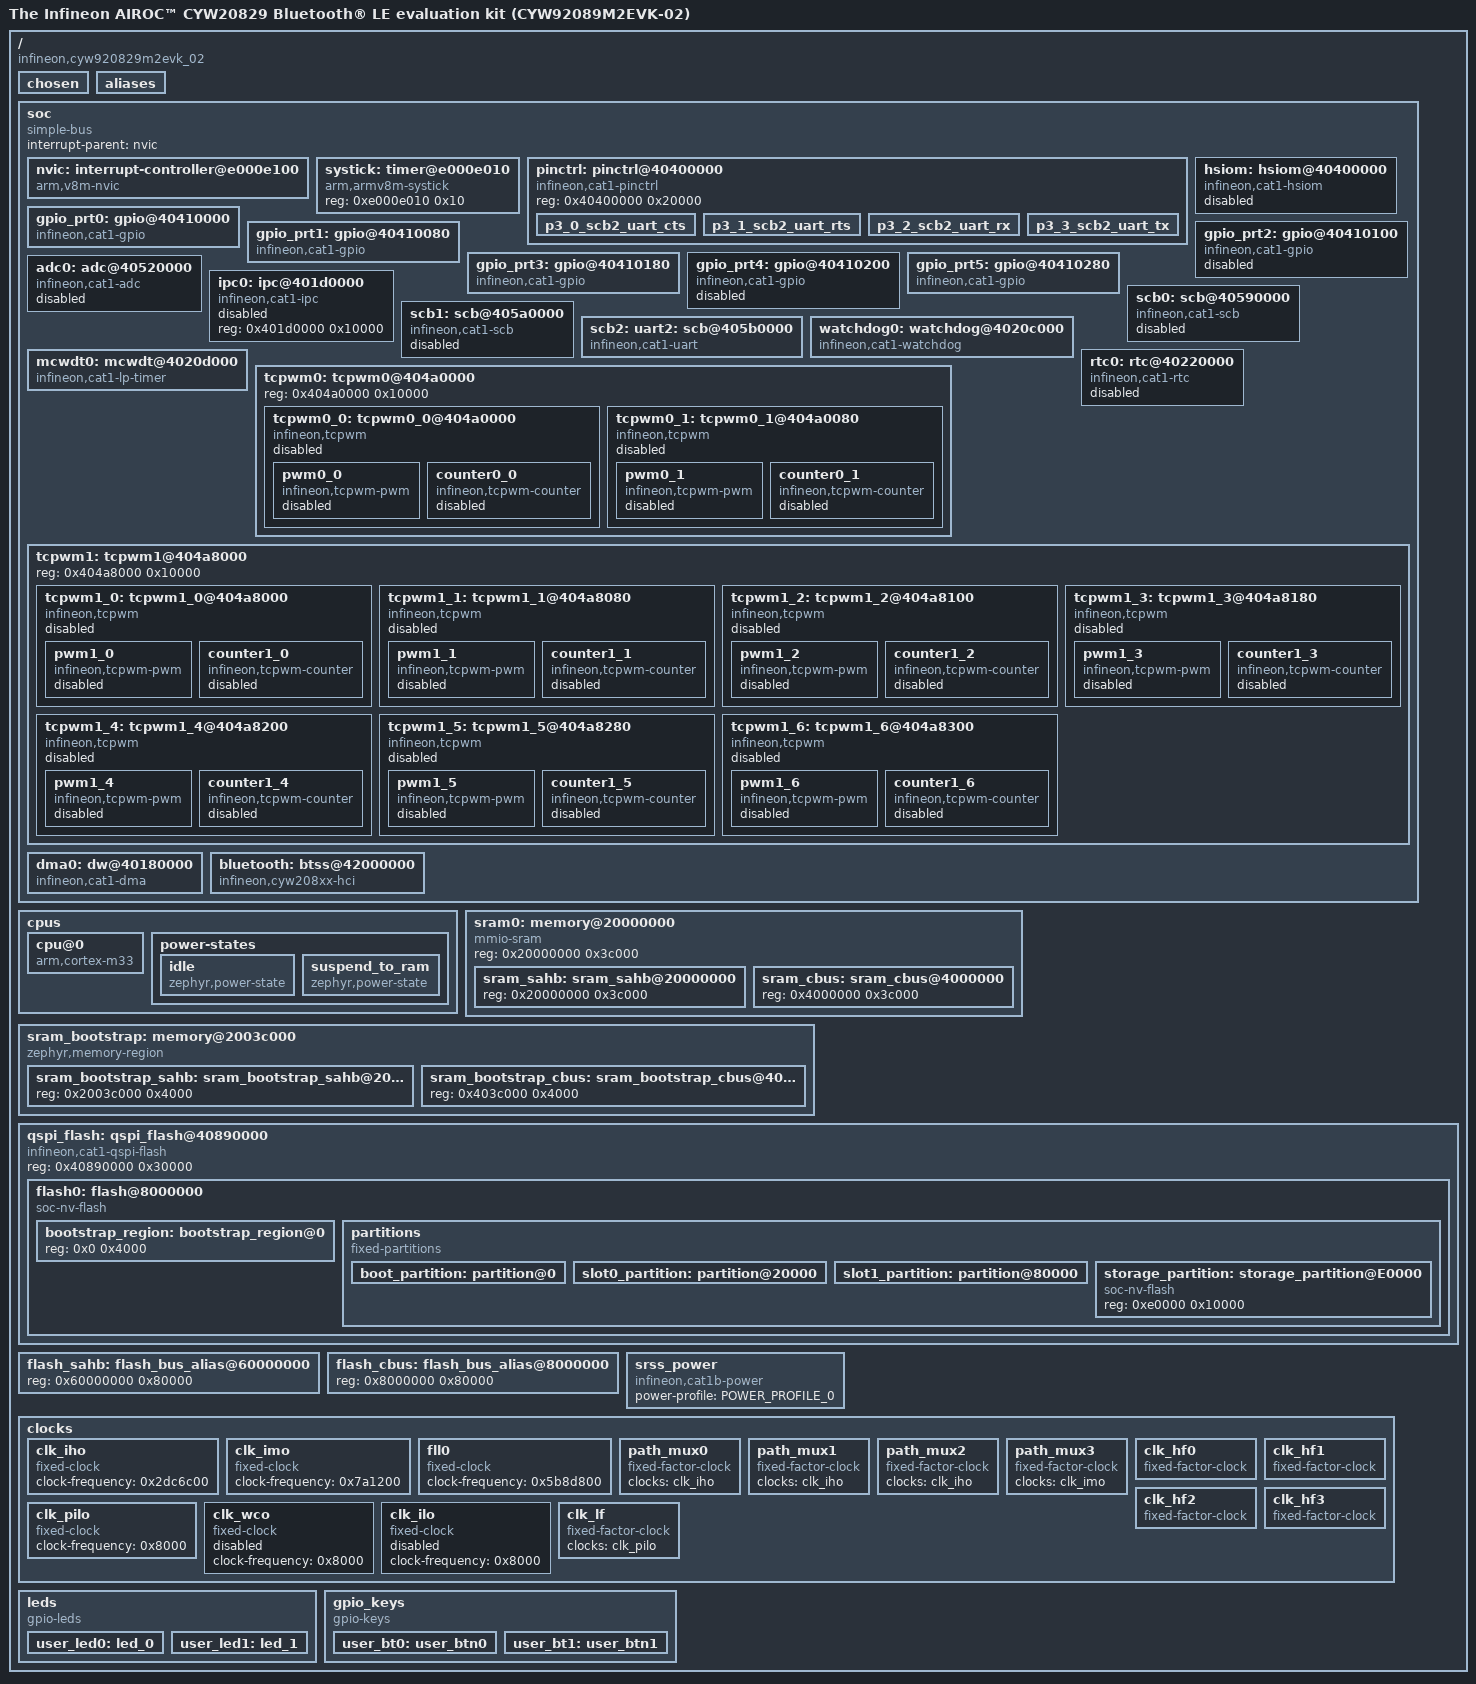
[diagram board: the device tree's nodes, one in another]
/dts-v1/;

/* node '/' defined in zephyr/dts/common/skeleton.dtsi:9 */
/ {
	#address-cells = < 0x1 >;                                                               /* in zephyr/dts/common/skeleton.dtsi:10 */
	#size-cells = < 0x1 >;                                                                  /* in zephyr/dts/common/skeleton.dtsi:11 */
	model = "The Infineon AIROC™ CYW20829 Bluetooth® LE evaluation kit (CYW92089M2EVK-02)"; /* in zephyr/boards/infineon/cyw920829m2evk_02/cyw920829m2evk_02.dts:13 */
	compatible = "infineon,cyw920829m2evk_02",
	             "infineon,CYW20829";                                                       /* in zephyr/boards/infineon/cyw920829m2evk_02/cyw920829m2evk_02.dts:14 */

	/* node '/chosen' defined in zephyr/dts/common/skeleton.dtsi:13 */
	chosen {
		zephyr,sram = &sram0;                     /* in zephyr/boards/infineon/cyw920829m2evk_02/cyw920829m2evk_02.dts:21 */
		zephyr,flash = &flash0;                   /* in zephyr/boards/infineon/cyw920829m2evk_02/cyw920829m2evk_02.dts:22 */
		zephyr,code-partition = &slot0_partition; /* in zephyr/boards/infineon/cyw920829m2evk_02/cyw920829m2evk_02.dts:23 */
		zephyr,console = &uart2;                  /* in zephyr/boards/infineon/cyw920829m2evk_02/cyw920829m2evk_02.dts:24 */
		zephyr,shell-uart = &uart2;               /* in zephyr/boards/infineon/cyw920829m2evk_02/cyw920829m2evk_02.dts:25 */
		zephyr,bt-hci = &bluetooth;               /* in zephyr/boards/infineon/cyw920829m2evk_02/cyw920829m2evk_02.dts:26 */
	};

	/* node '/aliases' defined in zephyr/dts/common/skeleton.dtsi:15 */
	aliases {
		led0 = &user_led0;      /* in zephyr/boards/infineon/cyw920829m2evk_02/cyw920829m2evk_02-common.dtsi:10 */
		led1 = &user_led1;      /* in zephyr/boards/infineon/cyw920829m2evk_02/cyw920829m2evk_02-common.dtsi:11 */
		sw0 = &user_bt0;        /* in zephyr/boards/infineon/cyw920829m2evk_02/cyw920829m2evk_02-common.dtsi:12 */
		sw1 = &user_bt1;        /* in zephyr/boards/infineon/cyw920829m2evk_02/cyw920829m2evk_02-common.dtsi:13 */
		watchdog0 = &watchdog0; /* in zephyr/boards/infineon/cyw920829m2evk_02/cyw920829m2evk_02.dts:17 */
	};

	/* node '/soc' defined in zephyr/dts/arm/armv8-m.dtsi:6 */
	soc {
		#address-cells = < 0x1 >;     /* in zephyr/dts/arm/armv8-m.dtsi:7 */
		#size-cells = < 0x1 >;        /* in zephyr/dts/arm/armv8-m.dtsi:8 */
		compatible = "simple-bus";    /* in zephyr/dts/arm/armv8-m.dtsi:9 */
		interrupt-parent = < &nvic >; /* in zephyr/dts/arm/armv8-m.dtsi:10 */
		ranges;                       /* in zephyr/dts/arm/armv8-m.dtsi:11 */

		/* node '/soc/interrupt-controller@e000e100' defined in zephyr/dts/arm/armv8-m.dtsi:13 */
		nvic: interrupt-controller@e000e100 {
			#address-cells = < 0x1 >;            /* in zephyr/dts/arm/armv8-m.dtsi:14 */
			compatible = "arm,v8m-nvic";         /* in zephyr/dts/arm/armv8-m.dtsi:15 */
			reg = < 0xe000e100 0xc00 >;          /* in zephyr/dts/arm/armv8-m.dtsi:16 */
			interrupt-controller;                /* in zephyr/dts/arm/armv8-m.dtsi:17 */
			#interrupt-cells = < 0x2 >;          /* in zephyr/dts/arm/armv8-m.dtsi:18 */
			arm,num-irq-priority-bits = < 0x3 >; /* in zephyr/boards/infineon/cyw920829m2evk_02/cyw920829m2evk_02.dts:31 */
			phandle = < 0x1 >;                   /* in zephyr/dts/arm/armv8-m.dtsi:10 */
		};

		/* node '/soc/timer@e000e010' defined in zephyr/dts/arm/armv8-m.dtsi:21 */
		systick: timer@e000e010 {
			compatible = "arm,armv8m-systick"; /* in zephyr/dts/arm/armv8-m.dtsi:22 */
			reg = < 0xe000e010 0x10 >;         /* in zephyr/dts/arm/armv8-m.dtsi:23 */
		};

		/* node '/soc/pinctrl@40400000' defined in zephyr/dts/arm/infineon/cat1b/cyw20829/cyw20829.dtsi:93 */
		pinctrl: pinctrl@40400000 {
			compatible = "infineon,cat1-pinctrl"; /* in zephyr/dts/arm/infineon/cat1b/cyw20829/cyw20829.dtsi:94 */
			reg = < 0x40400000 0x20000 >;         /* in zephyr/dts/arm/infineon/cat1b/cyw20829/cyw20829.dtsi:95 */

			/* node '/soc/pinctrl@40400000/p3_0_scb2_uart_cts' defined in zephyr/dts/arm/infineon/cat1b/cyw20829/cyw20829.56-qfn.dtsi:260 */
			p3_0_scb2_uart_cts: p3_0_scb2_uart_cts {
				pinmux = < 0x120003 >; /* in zephyr/dts/arm/infineon/cat1b/cyw20829/cyw20829.56-qfn.dtsi:261 */
				input-enable;          /* in zephyr/boards/infineon/cyw920829m2evk_02/cyw920829m2evk_02-pinctrl.dtsi:20 */
				phandle = < 0x5 >;     /* in zephyr/boards/infineon/cyw920829m2evk_02/cyw920829m2evk_02.dts:40 */
			};

			/* node '/soc/pinctrl@40400000/p3_1_scb2_uart_rts' defined in zephyr/dts/arm/infineon/cat1b/cyw20829/cyw20829.56-qfn.dtsi:277 */
			p3_1_scb2_uart_rts: p3_1_scb2_uart_rts {
				pinmux = < 0x120103 >; /* in zephyr/dts/arm/infineon/cat1b/cyw20829/cyw20829.56-qfn.dtsi:278 */
				drive-push-pull;       /* in zephyr/boards/infineon/cyw920829m2evk_02/cyw920829m2evk_02-pinctrl.dtsi:16 */
				phandle = < 0x4 >;     /* in zephyr/boards/infineon/cyw920829m2evk_02/cyw920829m2evk_02.dts:40 */
			};

			/* node '/soc/pinctrl@40400000/p3_2_scb2_uart_rx' defined in zephyr/dts/arm/infineon/cat1b/cyw20829/cyw20829.56-qfn.dtsi:286 */
			p3_2_scb2_uart_rx: p3_2_scb2_uart_rx {
				pinmux = < 0x120203 >; /* in zephyr/dts/arm/infineon/cat1b/cyw20829/cyw20829.56-qfn.dtsi:287 */
				input-enable;          /* in zephyr/boards/infineon/cyw920829m2evk_02/cyw920829m2evk_02-pinctrl.dtsi:12 */
				phandle = < 0x3 >;     /* in zephyr/boards/infineon/cyw920829m2evk_02/cyw920829m2evk_02.dts:40 */
			};

			/* node '/soc/pinctrl@40400000/p3_3_scb2_uart_tx' defined in zephyr/dts/arm/infineon/cat1b/cyw20829/cyw20829.56-qfn.dtsi:295 */
			p3_3_scb2_uart_tx: p3_3_scb2_uart_tx {
				pinmux = < 0x120303 >; /* in zephyr/dts/arm/infineon/cat1b/cyw20829/cyw20829.56-qfn.dtsi:296 */
				drive-push-pull;       /* in zephyr/boards/infineon/cyw920829m2evk_02/cyw920829m2evk_02-pinctrl.dtsi:8 */
				phandle = < 0x2 >;     /* in zephyr/boards/infineon/cyw920829m2evk_02/cyw920829m2evk_02.dts:40 */
			};
		};

		/* node '/soc/hsiom@40400000' defined in zephyr/dts/arm/infineon/cat1b/cyw20829/cyw20829.dtsi:98 */
		hsiom: hsiom@40400000 {
			compatible = "infineon,cat1-hsiom"; /* in zephyr/dts/arm/infineon/cat1b/cyw20829/cyw20829.dtsi:99 */
			reg = < 0x40400000 0x4000 >;        /* in zephyr/dts/arm/infineon/cat1b/cyw20829/cyw20829.dtsi:100 */
			interrupts = < 0x7 0x4 >,
			             < 0x6 0x4 >;           /* in zephyr/dts/arm/infineon/cat1b/cyw20829/cyw20829.dtsi:101 */
			status = "disabled";                /* in zephyr/dts/arm/infineon/cat1b/cyw20829/cyw20829.dtsi:102 */
		};

		/* node '/soc/gpio@40410000' defined in zephyr/dts/arm/infineon/cat1b/cyw20829/cyw20829.dtsi:105 */
		gpio_prt0: gpio@40410000 {
			compatible = "infineon,cat1-gpio"; /* in zephyr/dts/arm/infineon/cat1b/cyw20829/cyw20829.dtsi:106 */
			reg = < 0x40410000 0x80 >;         /* in zephyr/dts/arm/infineon/cat1b/cyw20829/cyw20829.dtsi:107 */
			interrupts = < 0x0 0x4 >;          /* in zephyr/dts/arm/infineon/cat1b/cyw20829/cyw20829.dtsi:108 */
			gpio-controller;                   /* in zephyr/dts/arm/infineon/cat1b/cyw20829/cyw20829.dtsi:109 */
			ngpios = < 0x6 >;                  /* in zephyr/dts/arm/infineon/cat1b/cyw20829/cyw20829.dtsi:110 */
			#gpio-cells = < 0x2 >;             /* in zephyr/dts/arm/infineon/cat1b/cyw20829/cyw20829.dtsi:112 */
			status = "okay";                   /* in zephyr/boards/infineon/cyw920829m2evk_02/cyw920829m2evk_02-common.dtsi:48 */
			phandle = < 0x11 >;                /* in zephyr/boards/infineon/cyw920829m2evk_02/cyw920829m2evk_02-common.dtsi:35 */
		};

		/* node '/soc/gpio@40410080' defined in zephyr/dts/arm/infineon/cat1b/cyw20829/cyw20829.dtsi:115 */
		gpio_prt1: gpio@40410080 {
			compatible = "infineon,cat1-gpio"; /* in zephyr/dts/arm/infineon/cat1b/cyw20829/cyw20829.dtsi:116 */
			reg = < 0x40410080 0x80 >;         /* in zephyr/dts/arm/infineon/cat1b/cyw20829/cyw20829.dtsi:117 */
			interrupts = < 0x1 0x4 >;          /* in zephyr/dts/arm/infineon/cat1b/cyw20829/cyw20829.dtsi:118 */
			gpio-controller;                   /* in zephyr/dts/arm/infineon/cat1b/cyw20829/cyw20829.dtsi:119 */
			ngpios = < 0x7 >;                  /* in zephyr/dts/arm/infineon/cat1b/cyw20829/cyw20829.dtsi:120 */
			#gpio-cells = < 0x2 >;             /* in zephyr/dts/arm/infineon/cat1b/cyw20829/cyw20829.dtsi:122 */
			status = "okay";                   /* in zephyr/boards/infineon/cyw920829m2evk_02/cyw920829m2evk_02-common.dtsi:52 */
			phandle = < 0xf >;                 /* in zephyr/boards/infineon/cyw920829m2evk_02/cyw920829m2evk_02-common.dtsi:21 */
		};

		/* node '/soc/gpio@40410100' defined in zephyr/dts/arm/infineon/cat1b/cyw20829/cyw20829.dtsi:125 */
		gpio_prt2: gpio@40410100 {
			compatible = "infineon,cat1-gpio"; /* in zephyr/dts/arm/infineon/cat1b/cyw20829/cyw20829.dtsi:126 */
			reg = < 0x40410100 0x80 >;         /* in zephyr/dts/arm/infineon/cat1b/cyw20829/cyw20829.dtsi:127 */
			interrupts = < 0x2 0x4 >;          /* in zephyr/dts/arm/infineon/cat1b/cyw20829/cyw20829.dtsi:128 */
			gpio-controller;                   /* in zephyr/dts/arm/infineon/cat1b/cyw20829/cyw20829.dtsi:129 */
			ngpios = < 0x6 >;                  /* in zephyr/dts/arm/infineon/cat1b/cyw20829/cyw20829.dtsi:130 */
			status = "disabled";               /* in zephyr/dts/arm/infineon/cat1b/cyw20829/cyw20829.dtsi:131 */
			#gpio-cells = < 0x2 >;             /* in zephyr/dts/arm/infineon/cat1b/cyw20829/cyw20829.dtsi:132 */
		};

		/* node '/soc/gpio@40410180' defined in zephyr/dts/arm/infineon/cat1b/cyw20829/cyw20829.dtsi:135 */
		gpio_prt3: gpio@40410180 {
			compatible = "infineon,cat1-gpio"; /* in zephyr/dts/arm/infineon/cat1b/cyw20829/cyw20829.dtsi:136 */
			reg = < 0x40410180 0x80 >;         /* in zephyr/dts/arm/infineon/cat1b/cyw20829/cyw20829.dtsi:137 */
			interrupts = < 0x3 0x4 >;          /* in zephyr/dts/arm/infineon/cat1b/cyw20829/cyw20829.dtsi:138 */
			gpio-controller;                   /* in zephyr/dts/arm/infineon/cat1b/cyw20829/cyw20829.dtsi:139 */
			ngpios = < 0x8 >;                  /* in zephyr/dts/arm/infineon/cat1b/cyw20829/cyw20829.dtsi:140 */
			#gpio-cells = < 0x2 >;             /* in zephyr/dts/arm/infineon/cat1b/cyw20829/cyw20829.dtsi:142 */
			status = "okay";                   /* in zephyr/boards/infineon/cyw920829m2evk_02/cyw920829m2evk_02-common.dtsi:56 */
		};

		/* node '/soc/gpio@40410200' defined in zephyr/dts/arm/infineon/cat1b/cyw20829/cyw20829.dtsi:145 */
		gpio_prt4: gpio@40410200 {
			compatible = "infineon,cat1-gpio"; /* in zephyr/dts/arm/infineon/cat1b/cyw20829/cyw20829.dtsi:146 */
			reg = < 0x40410200 0x80 >;         /* in zephyr/dts/arm/infineon/cat1b/cyw20829/cyw20829.dtsi:147 */
			interrupts = < 0x4 0x4 >;          /* in zephyr/dts/arm/infineon/cat1b/cyw20829/cyw20829.dtsi:148 */
			gpio-controller;                   /* in zephyr/dts/arm/infineon/cat1b/cyw20829/cyw20829.dtsi:149 */
			ngpios = < 0x2 >;                  /* in zephyr/dts/arm/infineon/cat1b/cyw20829/cyw20829.dtsi:150 */
			status = "disabled";               /* in zephyr/dts/arm/infineon/cat1b/cyw20829/cyw20829.dtsi:151 */
			#gpio-cells = < 0x2 >;             /* in zephyr/dts/arm/infineon/cat1b/cyw20829/cyw20829.dtsi:152 */
		};

		/* node '/soc/gpio@40410280' defined in zephyr/dts/arm/infineon/cat1b/cyw20829/cyw20829.dtsi:155 */
		gpio_prt5: gpio@40410280 {
			compatible = "infineon,cat1-gpio"; /* in zephyr/dts/arm/infineon/cat1b/cyw20829/cyw20829.dtsi:156 */
			reg = < 0x40410280 0x80 >;         /* in zephyr/dts/arm/infineon/cat1b/cyw20829/cyw20829.dtsi:157 */
			interrupts = < 0x5 0x4 >;          /* in zephyr/dts/arm/infineon/cat1b/cyw20829/cyw20829.dtsi:158 */
			gpio-controller;                   /* in zephyr/dts/arm/infineon/cat1b/cyw20829/cyw20829.dtsi:159 */
			ngpios = < 0x3 >;                  /* in zephyr/dts/arm/infineon/cat1b/cyw20829/cyw20829.dtsi:160 */
			#gpio-cells = < 0x2 >;             /* in zephyr/dts/arm/infineon/cat1b/cyw20829/cyw20829.dtsi:162 */
			status = "okay";                   /* in zephyr/boards/infineon/cyw920829m2evk_02/cyw920829m2evk_02-common.dtsi:60 */
			phandle = < 0x10 >;                /* in zephyr/boards/infineon/cyw920829m2evk_02/cyw920829m2evk_02-common.dtsi:26 */
		};

		/* node '/soc/adc@40520000' defined in zephyr/dts/arm/infineon/cat1b/cyw20829/cyw20829.dtsi:165 */
		adc0: adc@40520000 {
			compatible = "infineon,cat1-adc"; /* in zephyr/dts/arm/infineon/cat1b/cyw20829/cyw20829.dtsi:166 */
			reg = < 0x40520000 0x10000 >;     /* in zephyr/dts/arm/infineon/cat1b/cyw20829/cyw20829.dtsi:167 */
			interrupts = < 0x43 0x6 >;        /* in zephyr/dts/arm/infineon/cat1b/cyw20829/cyw20829.dtsi:168 */
			status = "disabled";              /* in zephyr/dts/arm/infineon/cat1b/cyw20829/cyw20829.dtsi:169 */
			#io-channel-cells = < 0x1 >;      /* in zephyr/dts/arm/infineon/cat1b/cyw20829/cyw20829.dtsi:170 */
		};

		/* node '/soc/ipc@401d0000' defined in zephyr/dts/arm/infineon/cat1b/cyw20829/cyw20829.dtsi:173 */
		ipc0: ipc@401d0000 {
			compatible = "infineon,cat1-ipc"; /* in zephyr/dts/arm/infineon/cat1b/cyw20829/cyw20829.dtsi:174 */
			reg = < 0x401d0000 0x10000 >;     /* in zephyr/dts/arm/infineon/cat1b/cyw20829/cyw20829.dtsi:175 */
			status = "disabled";              /* in zephyr/dts/arm/infineon/cat1b/cyw20829/cyw20829.dtsi:176 */
			#ipc-config-cells = < 0x3 >;      /* in zephyr/dts/arm/infineon/cat1b/cyw20829/cyw20829.dtsi:177 */
		};

		/* node '/soc/scb@40590000' defined in zephyr/dts/arm/infineon/cat1b/cyw20829/cyw20829.dtsi:180 */
		scb0: scb@40590000 {
			compatible = "infineon,cat1-scb"; /* in zephyr/dts/arm/infineon/cat1b/cyw20829/cyw20829.dtsi:181 */
			reg = < 0x40590000 0xfd0 >;       /* in zephyr/dts/arm/infineon/cat1b/cyw20829/cyw20829.dtsi:182 */
			interrupts = < 0x8 0x4 >;         /* in zephyr/dts/arm/infineon/cat1b/cyw20829/cyw20829.dtsi:183 */
			status = "disabled";              /* in zephyr/dts/arm/infineon/cat1b/cyw20829/cyw20829.dtsi:184 */
		};

		/* node '/soc/scb@405a0000' defined in zephyr/dts/arm/infineon/cat1b/cyw20829/cyw20829.dtsi:187 */
		scb1: scb@405a0000 {
			compatible = "infineon,cat1-scb"; /* in zephyr/dts/arm/infineon/cat1b/cyw20829/cyw20829.dtsi:188 */
			reg = < 0x405a0000 0xfd0 >;       /* in zephyr/dts/arm/infineon/cat1b/cyw20829/cyw20829.dtsi:189 */
			interrupts = < 0x11 0x4 >;        /* in zephyr/dts/arm/infineon/cat1b/cyw20829/cyw20829.dtsi:190 */
			status = "disabled";              /* in zephyr/dts/arm/infineon/cat1b/cyw20829/cyw20829.dtsi:191 */
		};

		/* node '/soc/scb@405b0000' defined in zephyr/dts/arm/infineon/cat1b/cyw20829/cyw20829.dtsi:194 */
		scb2: uart2: scb@405b0000 {
			reg = < 0x405b0000 0xfd0 >;                                                                    /* in zephyr/dts/arm/infineon/cat1b/cyw20829/cyw20829.dtsi:196 */
			interrupts = < 0x12 0x4 >;                                                                     /* in zephyr/dts/arm/infineon/cat1b/cyw20829/cyw20829.dtsi:197 */
			compatible = "infineon,cat1-uart";                                                             /* in zephyr/boards/infineon/cyw920829m2evk_02/cyw920829m2evk_02.dts:35 */
			status = "okay";                                                                               /* in zephyr/boards/infineon/cyw920829m2evk_02/cyw920829m2evk_02.dts:36 */
			current-speed = < 0x1c200 >;                                                                   /* in zephyr/boards/infineon/cyw920829m2evk_02/cyw920829m2evk_02.dts:37 */
			hw-flow-control;                                                                               /* in zephyr/boards/infineon/cyw920829m2evk_02/cyw920829m2evk_02.dts:38 */
			pinctrl-0 = < &p3_3_scb2_uart_tx &p3_2_scb2_uart_rx &p3_1_scb2_uart_rts &p3_0_scb2_uart_cts >; /* in zephyr/boards/infineon/cyw920829m2evk_02/cyw920829m2evk_02.dts:40 */
			pinctrl-names = "default";                                                                     /* in zephyr/boards/infineon/cyw920829m2evk_02/cyw920829m2evk_02.dts:41 */
			dmas = < &dma0 0x8 >,
			       < &dma0 0x9 >;                                                                          /* in zephyr/boards/infineon/cyw920829m2evk_02/cyw920829m2evk_02.dts:43 */
			dma-names = "tx",
			            "rx";                                                                              /* in zephyr/boards/infineon/cyw920829m2evk_02/cyw920829m2evk_02.dts:44 */
		};

		/* node '/soc/watchdog@4020c000' defined in zephyr/dts/arm/infineon/cat1b/cyw20829/cyw20829.dtsi:201 */
		watchdog0: watchdog@4020c000 {
			compatible = "infineon,cat1-watchdog"; /* in zephyr/dts/arm/infineon/cat1b/cyw20829/cyw20829.dtsi:202 */
			reg = < 0x4020c000 0x10 >;             /* in zephyr/dts/arm/infineon/cat1b/cyw20829/cyw20829.dtsi:203 */
			interrupts = < 0xf 0x4 >;              /* in zephyr/dts/arm/infineon/cat1b/cyw20829/cyw20829.dtsi:204 */
			status = "okay";                       /* in zephyr/boards/infineon/cyw920829m2evk_02/cyw920829m2evk_02.dts:92 */
		};

		/* node '/soc/mcwdt@4020d000' defined in zephyr/dts/arm/infineon/cat1b/cyw20829/cyw20829.dtsi:208 */
		mcwdt0: mcwdt@4020d000 {
			compatible = "infineon,cat1-lp-timer"; /* in zephyr/dts/arm/infineon/cat1b/cyw20829/cyw20829.dtsi:209 */
			reg = < 0x4020d000 0x40 >;             /* in zephyr/dts/arm/infineon/cat1b/cyw20829/cyw20829.dtsi:210 */
			interrupts = < 0x9 0x4 >;              /* in zephyr/dts/arm/infineon/cat1b/cyw20829/cyw20829.dtsi:211 */
			status = "okay";                       /* in zephyr/boards/infineon/cyw920829m2evk_02/cyw920829m2evk_02.dts:96 */
		};

		/* node '/soc/rtc@40220000' defined in zephyr/dts/arm/infineon/cat1b/cyw20829/cyw20829.dtsi:215 */
		rtc0: rtc@40220000 {
			compatible = "infineon,cat1-rtc"; /* in zephyr/dts/arm/infineon/cat1b/cyw20829/cyw20829.dtsi:216 */
			reg = < 0x40220000 0x10000 >;     /* in zephyr/dts/arm/infineon/cat1b/cyw20829/cyw20829.dtsi:217 */
			interrupts = < 0xa 0x6 >;         /* in zephyr/dts/arm/infineon/cat1b/cyw20829/cyw20829.dtsi:218 */
			alarms-count = < 0x2 >;           /* in zephyr/dts/arm/infineon/cat1b/cyw20829/cyw20829.dtsi:219 */
			status = "disabled";              /* in zephyr/dts/arm/infineon/cat1b/cyw20829/cyw20829.dtsi:220 */
		};

		/* node '/soc/tcpwm0@404a0000' defined in zephyr/dts/arm/infineon/cat1b/cyw20829/cyw20829.dtsi:223 */
		tcpwm0: tcpwm0@404a0000 {
			reg = < 0x404a0000 0x10000 >; /* in zephyr/dts/arm/infineon/cat1b/cyw20829/cyw20829.dtsi:224 */
			#address-cells = < 0x1 >;     /* in zephyr/dts/arm/infineon/cat1b/cyw20829/cyw20829.dtsi:225 */
			#size-cells = < 0x1 >;        /* in zephyr/dts/arm/infineon/cat1b/cyw20829/cyw20829.dtsi:226 */

			/* node '/soc/tcpwm0@404a0000/tcpwm0_0@404a0000' defined in zephyr/dts/arm/infineon/cat1b/cyw20829/cyw20829.dtsi:228 */
			tcpwm0_0: tcpwm0_0@404a0000 {
				compatible = "infineon,tcpwm"; /* in zephyr/dts/arm/infineon/cat1b/cyw20829/cyw20829.dtsi:229 */
				reg = < 0x404a0000 0x80 >;     /* in zephyr/dts/arm/infineon/cat1b/cyw20829/cyw20829.dtsi:230 */
				interrupts = < 0x2a 0x4 >;     /* in zephyr/dts/arm/infineon/cat1b/cyw20829/cyw20829.dtsi:231 */
				resolution = < 0x20 >;         /* in zephyr/dts/arm/infineon/cat1b/cyw20829/cyw20829.dtsi:232 */
				status = "disabled";           /* in zephyr/dts/arm/infineon/cat1b/cyw20829/cyw20829.dtsi:233 */

				/* node '/soc/tcpwm0@404a0000/tcpwm0_0@404a0000/pwm0_0' defined in zephyr/dts/arm/infineon/cat1b/cyw20829/cyw20829.dtsi:235 */
				pwm0_0: pwm0_0 {
					compatible = "infineon,tcpwm-pwm"; /* in zephyr/dts/arm/infineon/cat1b/cyw20829/cyw20829.dtsi:236 */
					#pwm-cells = < 0x3 >;              /* in zephyr/dts/arm/infineon/cat1b/cyw20829/cyw20829.dtsi:237 */
					status = "disabled";               /* in zephyr/dts/arm/infineon/cat1b/cyw20829/cyw20829.dtsi:238 */
				};

				/* node '/soc/tcpwm0@404a0000/tcpwm0_0@404a0000/counter0_0' defined in zephyr/dts/arm/infineon/cat1b/cyw20829/cyw20829.dtsi:241 */
				counter0_0: counter0_0 {
					compatible = "infineon,tcpwm-counter"; /* in zephyr/dts/arm/infineon/cat1b/cyw20829/cyw20829.dtsi:242 */
					status = "disabled";                   /* in zephyr/dts/arm/infineon/cat1b/cyw20829/cyw20829.dtsi:243 */
				};
			};

			/* node '/soc/tcpwm0@404a0000/tcpwm0_1@404a0080' defined in zephyr/dts/arm/infineon/cat1b/cyw20829/cyw20829.dtsi:247 */
			tcpwm0_1: tcpwm0_1@404a0080 {
				compatible = "infineon,tcpwm"; /* in zephyr/dts/arm/infineon/cat1b/cyw20829/cyw20829.dtsi:248 */
				reg = < 0x404a0080 0x80 >;     /* in zephyr/dts/arm/infineon/cat1b/cyw20829/cyw20829.dtsi:249 */
				interrupts = < 0x2b 0x4 >;     /* in zephyr/dts/arm/infineon/cat1b/cyw20829/cyw20829.dtsi:250 */
				resolution = < 0x20 >;         /* in zephyr/dts/arm/infineon/cat1b/cyw20829/cyw20829.dtsi:251 */
				status = "disabled";           /* in zephyr/dts/arm/infineon/cat1b/cyw20829/cyw20829.dtsi:252 */

				/* node '/soc/tcpwm0@404a0000/tcpwm0_1@404a0080/pwm0_1' defined in zephyr/dts/arm/infineon/cat1b/cyw20829/cyw20829.dtsi:254 */
				pwm0_1: pwm0_1 {
					compatible = "infineon,tcpwm-pwm"; /* in zephyr/dts/arm/infineon/cat1b/cyw20829/cyw20829.dtsi:255 */
					#pwm-cells = < 0x3 >;              /* in zephyr/dts/arm/infineon/cat1b/cyw20829/cyw20829.dtsi:256 */
					status = "disabled";               /* in zephyr/dts/arm/infineon/cat1b/cyw20829/cyw20829.dtsi:257 */
				};

				/* node '/soc/tcpwm0@404a0000/tcpwm0_1@404a0080/counter0_1' defined in zephyr/dts/arm/infineon/cat1b/cyw20829/cyw20829.dtsi:260 */
				counter0_1: counter0_1 {
					compatible = "infineon,tcpwm-counter"; /* in zephyr/dts/arm/infineon/cat1b/cyw20829/cyw20829.dtsi:261 */
					status = "disabled";                   /* in zephyr/dts/arm/infineon/cat1b/cyw20829/cyw20829.dtsi:262 */
				};
			};
		};

		/* node '/soc/tcpwm1@404a8000' defined in zephyr/dts/arm/infineon/cat1b/cyw20829/cyw20829.dtsi:267 */
		tcpwm1: tcpwm1@404a8000 {
			reg = < 0x404a8000 0x10000 >; /* in zephyr/dts/arm/infineon/cat1b/cyw20829/cyw20829.dtsi:268 */
			#address-cells = < 0x1 >;     /* in zephyr/dts/arm/infineon/cat1b/cyw20829/cyw20829.dtsi:269 */
			#size-cells = < 0x1 >;        /* in zephyr/dts/arm/infineon/cat1b/cyw20829/cyw20829.dtsi:270 */

			/* node '/soc/tcpwm1@404a8000/tcpwm1_0@404a8000' defined in zephyr/dts/arm/infineon/cat1b/cyw20829/cyw20829.dtsi:272 */
			tcpwm1_0: tcpwm1_0@404a8000 {
				compatible = "infineon,tcpwm"; /* in zephyr/dts/arm/infineon/cat1b/cyw20829/cyw20829.dtsi:273 */
				reg = < 0x404a8000 0x80 >;     /* in zephyr/dts/arm/infineon/cat1b/cyw20829/cyw20829.dtsi:274 */
				interrupts = < 0x2c 0x4 >;     /* in zephyr/dts/arm/infineon/cat1b/cyw20829/cyw20829.dtsi:275 */
				resolution = < 0x10 >;         /* in zephyr/dts/arm/infineon/cat1b/cyw20829/cyw20829.dtsi:276 */
				status = "disabled";           /* in zephyr/dts/arm/infineon/cat1b/cyw20829/cyw20829.dtsi:277 */

				/* node '/soc/tcpwm1@404a8000/tcpwm1_0@404a8000/pwm1_0' defined in zephyr/dts/arm/infineon/cat1b/cyw20829/cyw20829.dtsi:279 */
				pwm1_0: pwm1_0 {
					compatible = "infineon,tcpwm-pwm"; /* in zephyr/dts/arm/infineon/cat1b/cyw20829/cyw20829.dtsi:280 */
					#pwm-cells = < 0x3 >;              /* in zephyr/dts/arm/infineon/cat1b/cyw20829/cyw20829.dtsi:281 */
					status = "disabled";               /* in zephyr/dts/arm/infineon/cat1b/cyw20829/cyw20829.dtsi:282 */
				};

				/* node '/soc/tcpwm1@404a8000/tcpwm1_0@404a8000/counter1_0' defined in zephyr/dts/arm/infineon/cat1b/cyw20829/cyw20829.dtsi:285 */
				counter1_0: counter1_0 {
					compatible = "infineon,tcpwm-counter"; /* in zephyr/dts/arm/infineon/cat1b/cyw20829/cyw20829.dtsi:286 */
					status = "disabled";                   /* in zephyr/dts/arm/infineon/cat1b/cyw20829/cyw20829.dtsi:287 */
				};
			};

			/* node '/soc/tcpwm1@404a8000/tcpwm1_1@404a8080' defined in zephyr/dts/arm/infineon/cat1b/cyw20829/cyw20829.dtsi:291 */
			tcpwm1_1: tcpwm1_1@404a8080 {
				compatible = "infineon,tcpwm"; /* in zephyr/dts/arm/infineon/cat1b/cyw20829/cyw20829.dtsi:292 */
				reg = < 0x404a8080 0x80 >;     /* in zephyr/dts/arm/infineon/cat1b/cyw20829/cyw20829.dtsi:293 */
				interrupts = < 0x2d 0x4 >;     /* in zephyr/dts/arm/infineon/cat1b/cyw20829/cyw20829.dtsi:294 */
				resolution = < 0x10 >;         /* in zephyr/dts/arm/infineon/cat1b/cyw20829/cyw20829.dtsi:295 */
				status = "disabled";           /* in zephyr/dts/arm/infineon/cat1b/cyw20829/cyw20829.dtsi:296 */

				/* node '/soc/tcpwm1@404a8000/tcpwm1_1@404a8080/pwm1_1' defined in zephyr/dts/arm/infineon/cat1b/cyw20829/cyw20829.dtsi:298 */
				pwm1_1: pwm1_1 {
					compatible = "infineon,tcpwm-pwm"; /* in zephyr/dts/arm/infineon/cat1b/cyw20829/cyw20829.dtsi:299 */
					#pwm-cells = < 0x3 >;              /* in zephyr/dts/arm/infineon/cat1b/cyw20829/cyw20829.dtsi:300 */
					status = "disabled";               /* in zephyr/dts/arm/infineon/cat1b/cyw20829/cyw20829.dtsi:301 */
				};

				/* node '/soc/tcpwm1@404a8000/tcpwm1_1@404a8080/counter1_1' defined in zephyr/dts/arm/infineon/cat1b/cyw20829/cyw20829.dtsi:304 */
				counter1_1: counter1_1 {
					compatible = "infineon,tcpwm-counter"; /* in zephyr/dts/arm/infineon/cat1b/cyw20829/cyw20829.dtsi:305 */
					status = "disabled";                   /* in zephyr/dts/arm/infineon/cat1b/cyw20829/cyw20829.dtsi:306 */
				};
			};

			/* node '/soc/tcpwm1@404a8000/tcpwm1_2@404a8100' defined in zephyr/dts/arm/infineon/cat1b/cyw20829/cyw20829.dtsi:310 */
			tcpwm1_2: tcpwm1_2@404a8100 {
				compatible = "infineon,tcpwm"; /* in zephyr/dts/arm/infineon/cat1b/cyw20829/cyw20829.dtsi:311 */
				reg = < 0x404a8100 0x80 >;     /* in zephyr/dts/arm/infineon/cat1b/cyw20829/cyw20829.dtsi:312 */
				interrupts = < 0x2e 0x4 >;     /* in zephyr/dts/arm/infineon/cat1b/cyw20829/cyw20829.dtsi:313 */
				resolution = < 0x10 >;         /* in zephyr/dts/arm/infineon/cat1b/cyw20829/cyw20829.dtsi:314 */
				status = "disabled";           /* in zephyr/dts/arm/infineon/cat1b/cyw20829/cyw20829.dtsi:315 */

				/* node '/soc/tcpwm1@404a8000/tcpwm1_2@404a8100/pwm1_2' defined in zephyr/dts/arm/infineon/cat1b/cyw20829/cyw20829.dtsi:317 */
				pwm1_2: pwm1_2 {
					compatible = "infineon,tcpwm-pwm"; /* in zephyr/dts/arm/infineon/cat1b/cyw20829/cyw20829.dtsi:318 */
					#pwm-cells = < 0x3 >;              /* in zephyr/dts/arm/infineon/cat1b/cyw20829/cyw20829.dtsi:319 */
					status = "disabled";               /* in zephyr/dts/arm/infineon/cat1b/cyw20829/cyw20829.dtsi:320 */
				};

				/* node '/soc/tcpwm1@404a8000/tcpwm1_2@404a8100/counter1_2' defined in zephyr/dts/arm/infineon/cat1b/cyw20829/cyw20829.dtsi:323 */
				counter1_2: counter1_2 {
					compatible = "infineon,tcpwm-counter"; /* in zephyr/dts/arm/infineon/cat1b/cyw20829/cyw20829.dtsi:324 */
					status = "disabled";                   /* in zephyr/dts/arm/infineon/cat1b/cyw20829/cyw20829.dtsi:325 */
				};
			};

			/* node '/soc/tcpwm1@404a8000/tcpwm1_3@404a8180' defined in zephyr/dts/arm/infineon/cat1b/cyw20829/cyw20829.dtsi:329 */
			tcpwm1_3: tcpwm1_3@404a8180 {
				compatible = "infineon,tcpwm"; /* in zephyr/dts/arm/infineon/cat1b/cyw20829/cyw20829.dtsi:330 */
				reg = < 0x404a8180 0x80 >;     /* in zephyr/dts/arm/infineon/cat1b/cyw20829/cyw20829.dtsi:331 */
				interrupts = < 0x2f 0x4 >;     /* in zephyr/dts/arm/infineon/cat1b/cyw20829/cyw20829.dtsi:332 */
				resolution = < 0x10 >;         /* in zephyr/dts/arm/infineon/cat1b/cyw20829/cyw20829.dtsi:333 */
				status = "disabled";           /* in zephyr/dts/arm/infineon/cat1b/cyw20829/cyw20829.dtsi:334 */

				/* node '/soc/tcpwm1@404a8000/tcpwm1_3@404a8180/pwm1_3' defined in zephyr/dts/arm/infineon/cat1b/cyw20829/cyw20829.dtsi:336 */
				pwm1_3: pwm1_3 {
					compatible = "infineon,tcpwm-pwm"; /* in zephyr/dts/arm/infineon/cat1b/cyw20829/cyw20829.dtsi:337 */
					#pwm-cells = < 0x3 >;              /* in zephyr/dts/arm/infineon/cat1b/cyw20829/cyw20829.dtsi:338 */
					status = "disabled";               /* in zephyr/dts/arm/infineon/cat1b/cyw20829/cyw20829.dtsi:339 */
				};

				/* node '/soc/tcpwm1@404a8000/tcpwm1_3@404a8180/counter1_3' defined in zephyr/dts/arm/infineon/cat1b/cyw20829/cyw20829.dtsi:342 */
				counter1_3: counter1_3 {
					compatible = "infineon,tcpwm-counter"; /* in zephyr/dts/arm/infineon/cat1b/cyw20829/cyw20829.dtsi:343 */
					status = "disabled";                   /* in zephyr/dts/arm/infineon/cat1b/cyw20829/cyw20829.dtsi:344 */
				};
			};

			/* node '/soc/tcpwm1@404a8000/tcpwm1_4@404a8200' defined in zephyr/dts/arm/infineon/cat1b/cyw20829/cyw20829.dtsi:348 */
			tcpwm1_4: tcpwm1_4@404a8200 {
				compatible = "infineon,tcpwm"; /* in zephyr/dts/arm/infineon/cat1b/cyw20829/cyw20829.dtsi:349 */
				reg = < 0x404a8200 0x80 >;     /* in zephyr/dts/arm/infineon/cat1b/cyw20829/cyw20829.dtsi:350 */
				interrupts = < 0x30 0x4 >;     /* in zephyr/dts/arm/infineon/cat1b/cyw20829/cyw20829.dtsi:351 */
				resolution = < 0x10 >;         /* in zephyr/dts/arm/infineon/cat1b/cyw20829/cyw20829.dtsi:352 */
				status = "disabled";           /* in zephyr/dts/arm/infineon/cat1b/cyw20829/cyw20829.dtsi:353 */

				/* node '/soc/tcpwm1@404a8000/tcpwm1_4@404a8200/pwm1_4' defined in zephyr/dts/arm/infineon/cat1b/cyw20829/cyw20829.dtsi:355 */
				pwm1_4: pwm1_4 {
					compatible = "infineon,tcpwm-pwm"; /* in zephyr/dts/arm/infineon/cat1b/cyw20829/cyw20829.dtsi:356 */
					#pwm-cells = < 0x3 >;              /* in zephyr/dts/arm/infineon/cat1b/cyw20829/cyw20829.dtsi:357 */
					status = "disabled";               /* in zephyr/dts/arm/infineon/cat1b/cyw20829/cyw20829.dtsi:358 */
				};

				/* node '/soc/tcpwm1@404a8000/tcpwm1_4@404a8200/counter1_4' defined in zephyr/dts/arm/infineon/cat1b/cyw20829/cyw20829.dtsi:361 */
				counter1_4: counter1_4 {
					compatible = "infineon,tcpwm-counter"; /* in zephyr/dts/arm/infineon/cat1b/cyw20829/cyw20829.dtsi:362 */
					status = "disabled";                   /* in zephyr/dts/arm/infineon/cat1b/cyw20829/cyw20829.dtsi:363 */
				};
			};

			/* node '/soc/tcpwm1@404a8000/tcpwm1_5@404a8280' defined in zephyr/dts/arm/infineon/cat1b/cyw20829/cyw20829.dtsi:367 */
			tcpwm1_5: tcpwm1_5@404a8280 {
				compatible = "infineon,tcpwm"; /* in zephyr/dts/arm/infineon/cat1b/cyw20829/cyw20829.dtsi:368 */
				reg = < 0x404a8280 0x80 >;     /* in zephyr/dts/arm/infineon/cat1b/cyw20829/cyw20829.dtsi:369 */
				interrupts = < 0x31 0x4 >;     /* in zephyr/dts/arm/infineon/cat1b/cyw20829/cyw20829.dtsi:370 */
				resolution = < 0x10 >;         /* in zephyr/dts/arm/infineon/cat1b/cyw20829/cyw20829.dtsi:371 */
				status = "disabled";           /* in zephyr/dts/arm/infineon/cat1b/cyw20829/cyw20829.dtsi:372 */

				/* node '/soc/tcpwm1@404a8000/tcpwm1_5@404a8280/pwm1_5' defined in zephyr/dts/arm/infineon/cat1b/cyw20829/cyw20829.dtsi:374 */
				pwm1_5: pwm1_5 {
					compatible = "infineon,tcpwm-pwm"; /* in zephyr/dts/arm/infineon/cat1b/cyw20829/cyw20829.dtsi:375 */
					#pwm-cells = < 0x3 >;              /* in zephyr/dts/arm/infineon/cat1b/cyw20829/cyw20829.dtsi:376 */
					status = "disabled";               /* in zephyr/dts/arm/infineon/cat1b/cyw20829/cyw20829.dtsi:377 */
				};

				/* node '/soc/tcpwm1@404a8000/tcpwm1_5@404a8280/counter1_5' defined in zephyr/dts/arm/infineon/cat1b/cyw20829/cyw20829.dtsi:380 */
				counter1_5: counter1_5 {
					compatible = "infineon,tcpwm-counter"; /* in zephyr/dts/arm/infineon/cat1b/cyw20829/cyw20829.dtsi:381 */
					status = "disabled";                   /* in zephyr/dts/arm/infineon/cat1b/cyw20829/cyw20829.dtsi:382 */
				};
			};

			/* node '/soc/tcpwm1@404a8000/tcpwm1_6@404a8300' defined in zephyr/dts/arm/infineon/cat1b/cyw20829/cyw20829.dtsi:386 */
			tcpwm1_6: tcpwm1_6@404a8300 {
				compatible = "infineon,tcpwm"; /* in zephyr/dts/arm/infineon/cat1b/cyw20829/cyw20829.dtsi:387 */
				reg = < 0x404a8300 0x80 >;     /* in zephyr/dts/arm/infineon/cat1b/cyw20829/cyw20829.dtsi:388 */
				interrupts = < 0x32 0x4 >;     /* in zephyr/dts/arm/infineon/cat1b/cyw20829/cyw20829.dtsi:389 */
				resolution = < 0x10 >;         /* in zephyr/dts/arm/infineon/cat1b/cyw20829/cyw20829.dtsi:390 */
				status = "disabled";           /* in zephyr/dts/arm/infineon/cat1b/cyw20829/cyw20829.dtsi:391 */

				/* node '/soc/tcpwm1@404a8000/tcpwm1_6@404a8300/pwm1_6' defined in zephyr/dts/arm/infineon/cat1b/cyw20829/cyw20829.dtsi:393 */
				pwm1_6: pwm1_6 {
					compatible = "infineon,tcpwm-pwm"; /* in zephyr/dts/arm/infineon/cat1b/cyw20829/cyw20829.dtsi:394 */
					#pwm-cells = < 0x3 >;              /* in zephyr/dts/arm/infineon/cat1b/cyw20829/cyw20829.dtsi:395 */
					status = "disabled";               /* in zephyr/dts/arm/infineon/cat1b/cyw20829/cyw20829.dtsi:396 */
				};

				/* node '/soc/tcpwm1@404a8000/tcpwm1_6@404a8300/counter1_6' defined in zephyr/dts/arm/infineon/cat1b/cyw20829/cyw20829.dtsi:399 */
				counter1_6: counter1_6 {
					compatible = "infineon,tcpwm-counter"; /* in zephyr/dts/arm/infineon/cat1b/cyw20829/cyw20829.dtsi:400 */
					status = "disabled";                   /* in zephyr/dts/arm/infineon/cat1b/cyw20829/cyw20829.dtsi:401 */
				};
			};
		};

		/* node '/soc/dw@40180000' defined in zephyr/dts/arm/infineon/cat1b/cyw20829/cyw20829.dtsi:406 */
		dma0: dw@40180000 {
			#dma-cells = < 0x1 >;             /* in zephyr/dts/arm/infineon/cat1b/cyw20829/cyw20829.dtsi:407 */
			reg = < 0x40180000 0x10000 >;     /* in zephyr/dts/arm/infineon/cat1b/cyw20829/cyw20829.dtsi:409 */
			dma-channels = < 0x10 >;          /* in zephyr/dts/arm/infineon/cat1b/cyw20829/cyw20829.dtsi:410 */
			interrupts = < 0x13 0x4 >,
			             < 0x14 0x4 >,
			             < 0x15 0x4 >,
			             < 0x16 0x4 >,
			             < 0x17 0x4 >,
			             < 0x18 0x4 >,
			             < 0x19 0x4 >,
			             < 0x1a 0x4 >,
			             < 0x1b 0x4 >,
			             < 0x1c 0x4 >,
			             < 0x1d 0x4 >,
			             < 0x1e 0x4 >,
			             < 0x1f 0x4 >,
			             < 0x20 0x4 >,
			             < 0x21 0x4 >,
			             < 0x22 0x4 >;        /* in zephyr/dts/arm/infineon/cat1b/cyw20829/cyw20829.dtsi:411 */
			#address-cells = < 0x1 >;         /* in zephyr/boards/infineon/cyw920829m2evk_02/cyw920829m2evk_02.dts:48 */
			#size-cells = < 0x0 >;            /* in zephyr/boards/infineon/cyw920829m2evk_02/cyw920829m2evk_02.dts:49 */
			compatible = "infineon,cat1-dma"; /* in zephyr/boards/infineon/cyw920829m2evk_02/cyw920829m2evk_02.dts:50 */
			status = "okay";                  /* in zephyr/boards/infineon/cyw920829m2evk_02/cyw920829m2evk_02.dts:51 */
			phandle = < 0x6 >;                /* in zephyr/boards/infineon/cyw920829m2evk_02/cyw920829m2evk_02.dts:43 */
		};

		/* node '/soc/btss@42000000' defined in zephyr/dts/arm/infineon/cat1b/cyw20829/cyw20829.dtsi:430 */
		bluetooth: btss@42000000 {
			compatible = "infineon,cyw208xx-hci"; /* in zephyr/dts/arm/infineon/cat1b/cyw20829/cyw20829.dtsi:431 */
			reg = < 0x42000000 0x6186a0 >;        /* in zephyr/dts/arm/infineon/cat1b/cyw20829/cyw20829.dtsi:432 */
			interrupts = < 0x10 0x4 >;            /* in zephyr/dts/arm/infineon/cat1b/cyw20829/cyw20829.dtsi:433 */
			status = "okay";                      /* in zephyr/boards/infineon/cyw920829m2evk_02/cyw920829m2evk_02.dts:100 */
		};
	};

	/* node '/cpus' defined in zephyr/dts/arm/infineon/cat1b/cyw20829/cyw20829.dtsi:12 */
	cpus {
		#address-cells = < 0x1 >; /* in zephyr/dts/arm/infineon/cat1b/cyw20829/cyw20829.dtsi:13 */
		#size-cells = < 0x0 >;    /* in zephyr/dts/arm/infineon/cat1b/cyw20829/cyw20829.dtsi:14 */

		/* node '/cpus/cpu@0' defined in zephyr/dts/arm/infineon/cat1b/cyw20829/cyw20829.dtsi:16 */
		cpu@0 {
			device_type = "cpu";                          /* in zephyr/dts/arm/infineon/cat1b/cyw20829/cyw20829.dtsi:17 */
			compatible = "arm,cortex-m33";                /* in zephyr/dts/arm/infineon/cat1b/cyw20829/cyw20829.dtsi:18 */
			reg = < 0x0 >;                                /* in zephyr/dts/arm/infineon/cat1b/cyw20829/cyw20829.dtsi:19 */
			cpu-power-states = < &idle &suspend_to_ram >; /* in zephyr/dts/arm/infineon/cat1b/cyw20829/cyw20829.dtsi:20 */
		};

		/* node '/cpus/power-states' defined in zephyr/dts/arm/infineon/cat1b/cyw20829/cyw20829.dtsi:23 */
		power-states {

			/* node '/cpus/power-states/idle' defined in zephyr/dts/arm/infineon/cat1b/cyw20829/cyw20829.dtsi:24 */
			idle: idle {
				compatible = "zephyr,power-state";    /* in zephyr/dts/arm/infineon/cat1b/cyw20829/cyw20829.dtsi:25 */
				power-state-name = "suspend-to-idle"; /* in zephyr/dts/arm/infineon/cat1b/cyw20829/cyw20829.dtsi:26 */
				min-residency-us = < 0xf4240 >;       /* in zephyr/dts/arm/infineon/cat1b/cyw20829/cyw20829.dtsi:27 */
				phandle = < 0x7 >;                    /* in zephyr/dts/arm/infineon/cat1b/cyw20829/cyw20829.dtsi:20 */
			};

			/* node '/cpus/power-states/suspend_to_ram' defined in zephyr/dts/arm/infineon/cat1b/cyw20829/cyw20829.dtsi:30 */
			suspend_to_ram: suspend_to_ram {
				compatible = "zephyr,power-state";   /* in zephyr/dts/arm/infineon/cat1b/cyw20829/cyw20829.dtsi:31 */
				power-state-name = "suspend-to-ram"; /* in zephyr/dts/arm/infineon/cat1b/cyw20829/cyw20829.dtsi:32 */
				min-residency-us = < 0x1e8480 >;     /* in zephyr/dts/arm/infineon/cat1b/cyw20829/cyw20829.dtsi:33 */
				phandle = < 0x8 >;                   /* in zephyr/dts/arm/infineon/cat1b/cyw20829/cyw20829.dtsi:20 */
			};
		};
	};

	/* node '/memory@20000000' defined in zephyr/dts/arm/infineon/cat1b/cyw20829/cyw20829.dtsi:38 */
	sram0: memory@20000000 {
		#address-cells = < 0x1 >;     /* in zephyr/dts/arm/infineon/cat1b/cyw20829/cyw20829.dtsi:39 */
		#size-cells = < 0x1 >;        /* in zephyr/dts/arm/infineon/cat1b/cyw20829/cyw20829.dtsi:40 */
		compatible = "mmio-sram";     /* in zephyr/dts/arm/infineon/cat1b/cyw20829/cyw20829.dtsi:42 */
		reg = < 0x20000000 0x3c000 >; /* in zephyr/dts/arm/infineon/cat1b/cyw20829/cyw20829.dtsi:43 */

		/* node '/memory@20000000/sram_sahb@20000000' defined in zephyr/dts/arm/infineon/cat1b/cyw20829/cyw20829.dtsi:46 */
		sram_sahb: sram_sahb@20000000 {
			reg = < 0x20000000 0x3c000 >; /* in zephyr/dts/arm/infineon/cat1b/cyw20829/cyw20829.dtsi:47 */
		};

		/* node '/memory@20000000/sram_cbus@4000000' defined in zephyr/dts/arm/infineon/cat1b/cyw20829/cyw20829.dtsi:50 */
		sram_cbus: sram_cbus@4000000 {
			reg = < 0x4000000 0x3c000 >; /* in zephyr/dts/arm/infineon/cat1b/cyw20829/cyw20829.dtsi:51 */
		};
	};

	/* node '/memory@2003c000' defined in zephyr/dts/arm/infineon/cat1b/cyw20829/cyw20829.dtsi:59 */
	sram_bootstrap: memory@2003c000 {
		#address-cells = < 0x1 >;               /* in zephyr/dts/arm/infineon/cat1b/cyw20829/cyw20829.dtsi:60 */
		#size-cells = < 0x1 >;                  /* in zephyr/dts/arm/infineon/cat1b/cyw20829/cyw20829.dtsi:61 */
		compatible = "zephyr,memory-region",
		             "mmio-sram";               /* in zephyr/dts/arm/infineon/cat1b/cyw20829/cyw20829.dtsi:62 */
		zephyr,memory-region = "BOOTSTRAP_RAM"; /* in zephyr/dts/arm/infineon/cat1b/cyw20829/cyw20829.dtsi:63 */
		reg = < 0x2003c000 0x4000 >;            /* in zephyr/dts/arm/infineon/cat1b/cyw20829/cyw20829.dtsi:64 */

		/* node '/memory@2003c000/sram_bootstrap_sahb@2003c000' defined in zephyr/dts/arm/infineon/cat1b/cyw20829/cyw20829.dtsi:67 */
		sram_bootstrap_sahb: sram_bootstrap_sahb@2003c000 {
			reg = < 0x2003c000 0x4000 >; /* in zephyr/dts/arm/infineon/cat1b/cyw20829/cyw20829.dtsi:68 */
		};

		/* node '/memory@2003c000/sram_bootstrap_cbus@403c000' defined in zephyr/dts/arm/infineon/cat1b/cyw20829/cyw20829.dtsi:71 */
		sram_bootstrap_cbus: sram_bootstrap_cbus@403c000 {
			reg = < 0x403c000 0x4000 >; /* in zephyr/dts/arm/infineon/cat1b/cyw20829/cyw20829.dtsi:72 */
		};
	};

	/* node '/qspi_flash@40890000' defined in zephyr/dts/arm/infineon/cat1b/cyw20829/cyw20829.dtsi:76 */
	qspi_flash: qspi_flash@40890000 {
		compatible = "infineon,cat1-qspi-flash"; /* in zephyr/dts/arm/infineon/cat1b/cyw20829/cyw20829.dtsi:77 */
		reg = < 0x40890000 0x30000 >;            /* in zephyr/dts/arm/infineon/cat1b/cyw20829/cyw20829.dtsi:78 */
		#address-cells = < 0x1 >;                /* in zephyr/dts/arm/infineon/cat1b/cyw20829/cyw20829.dtsi:79 */
		#size-cells = < 0x1 >;                   /* in zephyr/dts/arm/infineon/cat1b/cyw20829/cyw20829.dtsi:80 */

		/* node '/qspi_flash@40890000/flash@8000000' defined in zephyr/boards/infineon/cyw920829m2evk_02/cyw920829m2evk_02.dts:104 */
		flash0: flash@8000000 {
			compatible = "soc-nv-flash";   /* in zephyr/boards/infineon/cyw920829m2evk_02/cyw920829m2evk_02.dts:105 */
			reg = < 0x8000000 0x100000 >;  /* in zephyr/boards/infineon/cyw920829m2evk_02/cyw920829m2evk_02.dts:106 */
			write-block-size = < 0x1 >;    /* in zephyr/boards/infineon/cyw920829m2evk_02/cyw920829m2evk_02.dts:107 */
			erase-block-size = < 0x1000 >; /* in zephyr/boards/infineon/cyw920829m2evk_02/cyw920829m2evk_02.dts:108 */
			#address-cells = < 0x1 >;      /* in zephyr/boards/infineon/cyw920829m2evk_02/cyw920829m2evk_02.dts:109 */
			#size-cells = < 0x1 >;         /* in zephyr/boards/infineon/cyw920829m2evk_02/cyw920829m2evk_02.dts:110 */

			/* node '/qspi_flash@40890000/flash@8000000/bootstrap_region@0' defined in zephyr/boards/infineon/cyw920829m2evk_02/cyw920829m2evk_02.dts:116 */
			bootstrap_region: bootstrap_region@0 {
				reg = < 0x0 0x4000 >; /* in zephyr/boards/infineon/cyw920829m2evk_02/cyw920829m2evk_02.dts:117 */
			};

			/* node '/qspi_flash@40890000/flash@8000000/partitions' defined in zephyr/boards/infineon/cyw920829m2evk_02/cyw920829m2evk_02.dts:120 */
			partitions {
				compatible = "fixed-partitions"; /* in zephyr/boards/infineon/cyw920829m2evk_02/cyw920829m2evk_02.dts:121 */
				#address-cells = < 0x1 >;        /* in zephyr/boards/infineon/cyw920829m2evk_02/cyw920829m2evk_02.dts:122 */
				#size-cells = < 0x1 >;           /* in zephyr/boards/infineon/cyw920829m2evk_02/cyw920829m2evk_02.dts:123 */

				/* node '/qspi_flash@40890000/flash@8000000/partitions/partition@0' defined in zephyr/boards/infineon/cyw920829m2evk_02/cyw920829m2evk_02.dts:125 */
				boot_partition: partition@0 {
					label = "mcuboot";     /* in zephyr/boards/infineon/cyw920829m2evk_02/cyw920829m2evk_02.dts:126 */
					reg = < 0x0 0x20000 >; /* in zephyr/boards/infineon/cyw920829m2evk_02/cyw920829m2evk_02.dts:127 */
					read-only;             /* in zephyr/boards/infineon/cyw920829m2evk_02/cyw920829m2evk_02.dts:128 */
				};

				/* node '/qspi_flash@40890000/flash@8000000/partitions/partition@20000' defined in zephyr/boards/infineon/cyw920829m2evk_02/cyw920829m2evk_02.dts:131 */
				slot0_partition: partition@20000 {
					label = "image-0";         /* in zephyr/boards/infineon/cyw920829m2evk_02/cyw920829m2evk_02.dts:132 */
					reg = < 0x20000 0x60000 >; /* in zephyr/boards/infineon/cyw920829m2evk_02/cyw920829m2evk_02.dts:133 */
				};

				/* node '/qspi_flash@40890000/flash@8000000/partitions/partition@80000' defined in zephyr/boards/infineon/cyw920829m2evk_02/cyw920829m2evk_02.dts:136 */
				slot1_partition: partition@80000 {
					label = "image-1";         /* in zephyr/boards/infineon/cyw920829m2evk_02/cyw920829m2evk_02.dts:137 */
					reg = < 0x80000 0x60000 >; /* in zephyr/boards/infineon/cyw920829m2evk_02/cyw920829m2evk_02.dts:138 */
				};

				/* node '/qspi_flash@40890000/flash@8000000/partitions/storage_partition@E0000' defined in zephyr/boards/infineon/cyw920829m2evk_02/cyw920829m2evk_02.dts:141 */
				storage_partition: storage_partition@E0000 {
					compatible = "soc-nv-flash"; /* in zephyr/boards/infineon/cyw920829m2evk_02/cyw920829m2evk_02.dts:142 */
					reg = < 0xe0000 0x10000 >;   /* in zephyr/boards/infineon/cyw920829m2evk_02/cyw920829m2evk_02.dts:143 */
				};
			};
		};
	};

	/* node '/flash_bus_alias@60000000' defined in zephyr/dts/arm/infineon/cat1b/cyw20829/cyw20829.dtsi:84 */
	flash_sahb: flash_bus_alias@60000000 {
		reg = < 0x60000000 0x80000 >; /* in zephyr/dts/arm/infineon/cat1b/cyw20829/cyw20829.dtsi:85 */
	};

	/* node '/flash_bus_alias@8000000' defined in zephyr/dts/arm/infineon/cat1b/cyw20829/cyw20829.dtsi:88 */
	flash_cbus: flash_bus_alias@8000000 {
		reg = < 0x8000000 0x80000 >; /* in zephyr/dts/arm/infineon/cat1b/cyw20829/cyw20829.dtsi:89 */
	};

	/* node '/srss_power' defined in zephyr/dts/arm/infineon/cat1b/cyw20829/system_clocks.dtsi:11 */
	srss_power: srss_power {
		#clock-cells = < 0x0 >;              /* in zephyr/dts/arm/infineon/cat1b/cyw20829/system_clocks.dtsi:12 */
		compatible = "infineon,cat1b-power"; /* in zephyr/dts/arm/infineon/cat1b/cyw20829/system_clocks.dtsi:13 */
		power-profile = "POWER_PROFILE_0";   /* in zephyr/dts/arm/infineon/cat1b/cyw20829/system_clocks.dtsi:14 */
		status = "okay";                     /* in zephyr/dts/arm/infineon/cat1b/cyw20829/system_clocks.dtsi:15 */
	};

	/* node '/clocks' defined in zephyr/dts/arm/infineon/cat1b/cyw20829/system_clocks.dtsi:18 */
	clocks {

		/* node '/clocks/clk_iho' defined in zephyr/dts/arm/infineon/cat1b/cyw20829/system_clocks.dtsi:20 */
		clk_iho: clk_iho {
			#clock-cells = < 0x0 >;          /* in zephyr/dts/arm/infineon/cat1b/cyw20829/system_clocks.dtsi:21 */
			compatible = "fixed-clock";      /* in zephyr/dts/arm/infineon/cat1b/cyw20829/system_clocks.dtsi:22 */
			clock-frequency = < 0x2dc6c00 >; /* in zephyr/dts/arm/infineon/cat1b/cyw20829/system_clocks.dtsi:23 */
			status = "okay";                 /* in zephyr/dts/arm/infineon/cat1b/cyw20829/system_clocks.dtsi:24 */
			phandle = < 0x9 >;               /* in zephyr/dts/arm/infineon/cat1b/cyw20829/system_clocks.dtsi:47 */
		};

		/* node '/clocks/clk_imo' defined in zephyr/dts/arm/infineon/cat1b/cyw20829/system_clocks.dtsi:28 */
		clk_imo: clk_imo {
			#clock-cells = < 0x0 >;         /* in zephyr/dts/arm/infineon/cat1b/cyw20829/system_clocks.dtsi:29 */
			compatible = "fixed-clock";     /* in zephyr/dts/arm/infineon/cat1b/cyw20829/system_clocks.dtsi:30 */
			clock-frequency = < 0x7a1200 >; /* in zephyr/dts/arm/infineon/cat1b/cyw20829/system_clocks.dtsi:31 */
			status = "okay";                /* in zephyr/dts/arm/infineon/cat1b/cyw20829/system_clocks.dtsi:32 */
			phandle = < 0xa >;              /* in zephyr/dts/arm/infineon/cat1b/cyw20829/system_clocks.dtsi:71 */
		};

		/* node '/clocks/fll0' defined in zephyr/dts/arm/infineon/cat1b/cyw20829/system_clocks.dtsi:36 */
		fll0: fll0 {
			#clock-cells = < 0x0 >;          /* in zephyr/dts/arm/infineon/cat1b/cyw20829/system_clocks.dtsi:37 */
			compatible = "fixed-clock";      /* in zephyr/dts/arm/infineon/cat1b/cyw20829/system_clocks.dtsi:38 */
			clock-frequency = < 0x5b8d800 >; /* in zephyr/dts/arm/infineon/cat1b/cyw20829/system_clocks.dtsi:39 */
			status = "okay";                 /* in zephyr/boards/infineon/cyw920829m2evk_02/cyw920829m2evk_02.dts:55 */
			phandle = < 0xb >;               /* in zephyr/boards/infineon/cyw920829m2evk_02/cyw920829m2evk_02.dts:76 */
		};

		/* node '/clocks/path_mux0' defined in zephyr/dts/arm/infineon/cat1b/cyw20829/system_clocks.dtsi:44 */
		path_mux0: path_mux0 {
			#clock-cells = < 0x0 >;            /* in zephyr/dts/arm/infineon/cat1b/cyw20829/system_clocks.dtsi:45 */
			compatible = "fixed-factor-clock"; /* in zephyr/dts/arm/infineon/cat1b/cyw20829/system_clocks.dtsi:46 */
			clocks = < &clk_iho >;             /* in zephyr/dts/arm/infineon/cat1b/cyw20829/system_clocks.dtsi:47 */
			status = "okay";                   /* in zephyr/boards/infineon/cyw920829m2evk_02/cyw920829m2evk_02.dts:59 */
		};

		/* node '/clocks/path_mux1' defined in zephyr/dts/arm/infineon/cat1b/cyw20829/system_clocks.dtsi:52 */
		path_mux1: path_mux1 {
			#clock-cells = < 0x0 >;            /* in zephyr/dts/arm/infineon/cat1b/cyw20829/system_clocks.dtsi:53 */
			compatible = "fixed-factor-clock"; /* in zephyr/dts/arm/infineon/cat1b/cyw20829/system_clocks.dtsi:54 */
			clocks = < &clk_iho >;             /* in zephyr/dts/arm/infineon/cat1b/cyw20829/system_clocks.dtsi:55 */
			status = "okay";                   /* in zephyr/boards/infineon/cyw920829m2evk_02/cyw920829m2evk_02.dts:63 */
			phandle = < 0xd >;                 /* in zephyr/dts/arm/infineon/cat1b/cyw20829/system_clocks.dtsi:107 */
		};

		/* node '/clocks/path_mux2' defined in zephyr/dts/arm/infineon/cat1b/cyw20829/system_clocks.dtsi:60 */
		path_mux2: path_mux2 {
			#clock-cells = < 0x0 >;            /* in zephyr/dts/arm/infineon/cat1b/cyw20829/system_clocks.dtsi:61 */
			compatible = "fixed-factor-clock"; /* in zephyr/dts/arm/infineon/cat1b/cyw20829/system_clocks.dtsi:62 */
			clocks = < &clk_iho >;             /* in zephyr/dts/arm/infineon/cat1b/cyw20829/system_clocks.dtsi:63 */
			status = "okay";                   /* in zephyr/boards/infineon/cyw920829m2evk_02/cyw920829m2evk_02.dts:67 */
			phandle = < 0xc >;                 /* in zephyr/dts/arm/infineon/cat1b/cyw20829/system_clocks.dtsi:98 */
		};

		/* node '/clocks/path_mux3' defined in zephyr/dts/arm/infineon/cat1b/cyw20829/system_clocks.dtsi:68 */
		path_mux3: path_mux3 {
			#clock-cells = < 0x0 >;            /* in zephyr/dts/arm/infineon/cat1b/cyw20829/system_clocks.dtsi:69 */
			compatible = "fixed-factor-clock"; /* in zephyr/dts/arm/infineon/cat1b/cyw20829/system_clocks.dtsi:70 */
			clocks = < &clk_imo >;             /* in zephyr/dts/arm/infineon/cat1b/cyw20829/system_clocks.dtsi:71 */
			status = "okay";                   /* in zephyr/boards/infineon/cyw920829m2evk_02/cyw920829m2evk_02.dts:71 */
		};

		/* node '/clocks/clk_hf0' defined in zephyr/dts/arm/infineon/cat1b/cyw20829/system_clocks.dtsi:76 */
		clk_hf0: clk_hf0 {
			#clock-cells = < 0x0 >;            /* in zephyr/dts/arm/infineon/cat1b/cyw20829/system_clocks.dtsi:77 */
			compatible = "fixed-factor-clock"; /* in zephyr/dts/arm/infineon/cat1b/cyw20829/system_clocks.dtsi:78 */
			clock-div = < 0x1 >;               /* in zephyr/dts/arm/infineon/cat1b/cyw20829/system_clocks.dtsi:79 */
			status = "okay";                   /* in zephyr/boards/infineon/cyw920829m2evk_02/cyw920829m2evk_02.dts:75 */
			clocks = < &fll0 >;                /* in zephyr/boards/infineon/cyw920829m2evk_02/cyw920829m2evk_02.dts:76 */
		};

		/* node '/clocks/clk_hf1' defined in zephyr/dts/arm/infineon/cat1b/cyw20829/system_clocks.dtsi:85 */
		clk_hf1: clk_hf1 {
			#clock-cells = < 0x0 >;            /* in zephyr/dts/arm/infineon/cat1b/cyw20829/system_clocks.dtsi:86 */
			compatible = "fixed-factor-clock"; /* in zephyr/dts/arm/infineon/cat1b/cyw20829/system_clocks.dtsi:87 */
			clock-div = < 0x1 >;               /* in zephyr/dts/arm/infineon/cat1b/cyw20829/system_clocks.dtsi:88 */
			clocks = < &fll0 >;                /* in zephyr/dts/arm/infineon/cat1b/cyw20829/system_clocks.dtsi:89 */
			status = "okay";                   /* in zephyr/boards/infineon/cyw920829m2evk_02/cyw920829m2evk_02.dts:80 */
		};

		/* node '/clocks/clk_hf2' defined in zephyr/dts/arm/infineon/cat1b/cyw20829/system_clocks.dtsi:94 */
		clk_hf2: clk_hf2 {
			#clock-cells = < 0x0 >;            /* in zephyr/dts/arm/infineon/cat1b/cyw20829/system_clocks.dtsi:95 */
			compatible = "fixed-factor-clock"; /* in zephyr/dts/arm/infineon/cat1b/cyw20829/system_clocks.dtsi:96 */
			clock-div = < 0x1 >;               /* in zephyr/dts/arm/infineon/cat1b/cyw20829/system_clocks.dtsi:97 */
			clocks = < &path_mux2 >;           /* in zephyr/dts/arm/infineon/cat1b/cyw20829/system_clocks.dtsi:98 */
			status = "okay";                   /* in zephyr/boards/infineon/cyw920829m2evk_02/cyw920829m2evk_02.dts:84 */
		};

		/* node '/clocks/clk_hf3' defined in zephyr/dts/arm/infineon/cat1b/cyw20829/system_clocks.dtsi:103 */
		clk_hf3: clk_hf3 {
			#clock-cells = < 0x0 >;            /* in zephyr/dts/arm/infineon/cat1b/cyw20829/system_clocks.dtsi:104 */
			compatible = "fixed-factor-clock"; /* in zephyr/dts/arm/infineon/cat1b/cyw20829/system_clocks.dtsi:105 */
			clock-div = < 0x2 >;               /* in zephyr/dts/arm/infineon/cat1b/cyw20829/system_clocks.dtsi:106 */
			clocks = < &path_mux1 >;           /* in zephyr/dts/arm/infineon/cat1b/cyw20829/system_clocks.dtsi:107 */
			status = "okay";                   /* in zephyr/boards/infineon/cyw920829m2evk_02/cyw920829m2evk_02.dts:88 */
		};

		/* node '/clocks/clk_pilo' defined in zephyr/dts/arm/infineon/cat1b/cyw20829/system_clocks.dtsi:114 */
		clk_pilo: clk_pilo {
			#clock-cells = < 0x0 >;       /* in zephyr/dts/arm/infineon/cat1b/cyw20829/system_clocks.dtsi:115 */
			compatible = "fixed-clock";   /* in zephyr/dts/arm/infineon/cat1b/cyw20829/system_clocks.dtsi:116 */
			clock-frequency = < 0x8000 >; /* in zephyr/dts/arm/infineon/cat1b/cyw20829/system_clocks.dtsi:117 */
			status = "okay";              /* in zephyr/dts/arm/infineon/cat1b/cyw20829/system_clocks.dtsi:118 */
			phandle = < 0xe >;            /* in zephyr/dts/arm/infineon/cat1b/cyw20829/system_clocks.dtsi:141 */
		};

		/* node '/clocks/clk_wco' defined in zephyr/dts/arm/infineon/cat1b/cyw20829/system_clocks.dtsi:122 */
		clk_wco: clk_wco {
			#clock-cells = < 0x0 >;       /* in zephyr/dts/arm/infineon/cat1b/cyw20829/system_clocks.dtsi:123 */
			compatible = "fixed-clock";   /* in zephyr/dts/arm/infineon/cat1b/cyw20829/system_clocks.dtsi:124 */
			clock-frequency = < 0x8000 >; /* in zephyr/dts/arm/infineon/cat1b/cyw20829/system_clocks.dtsi:125 */
			status = "disabled";          /* in zephyr/dts/arm/infineon/cat1b/cyw20829/system_clocks.dtsi:126 */
		};

		/* node '/clocks/clk_ilo' defined in zephyr/dts/arm/infineon/cat1b/cyw20829/system_clocks.dtsi:130 */
		clk_ilo: clk_ilo {
			#clock-cells = < 0x0 >;       /* in zephyr/dts/arm/infineon/cat1b/cyw20829/system_clocks.dtsi:131 */
			compatible = "fixed-clock";   /* in zephyr/dts/arm/infineon/cat1b/cyw20829/system_clocks.dtsi:132 */
			clock-frequency = < 0x8000 >; /* in zephyr/dts/arm/infineon/cat1b/cyw20829/system_clocks.dtsi:133 */
			status = "disabled";          /* in zephyr/dts/arm/infineon/cat1b/cyw20829/system_clocks.dtsi:134 */
		};

		/* node '/clocks/clk_lf' defined in zephyr/dts/arm/infineon/cat1b/cyw20829/system_clocks.dtsi:138 */
		clk_lf: clk_lf {
			#clock-cells = < 0x0 >;            /* in zephyr/dts/arm/infineon/cat1b/cyw20829/system_clocks.dtsi:139 */
			compatible = "fixed-factor-clock"; /* in zephyr/dts/arm/infineon/cat1b/cyw20829/system_clocks.dtsi:140 */
			clocks = < &clk_pilo >;            /* in zephyr/dts/arm/infineon/cat1b/cyw20829/system_clocks.dtsi:141 */
			status = "okay";                   /* in zephyr/dts/arm/infineon/cat1b/cyw20829/system_clocks.dtsi:142 */
		};
	};

	/* node '/leds' defined in zephyr/boards/infineon/cyw920829m2evk_02/cyw920829m2evk_02-common.dtsi:16 */
	leds {
		compatible = "gpio-leds"; /* in zephyr/boards/infineon/cyw920829m2evk_02/cyw920829m2evk_02-common.dtsi:17 */

		/* node '/leds/led_0' defined in zephyr/boards/infineon/cyw920829m2evk_02/cyw920829m2evk_02-common.dtsi:19 */
		user_led0: led_0 {
			label = "LED_0";                /* in zephyr/boards/infineon/cyw920829m2evk_02/cyw920829m2evk_02-common.dtsi:20 */
			gpios = < &gpio_prt1 0x1 0x1 >; /* in zephyr/boards/infineon/cyw920829m2evk_02/cyw920829m2evk_02-common.dtsi:21 */
		};

		/* node '/leds/led_1' defined in zephyr/boards/infineon/cyw920829m2evk_02/cyw920829m2evk_02-common.dtsi:24 */
		user_led1: led_1 {
			label = "LED_1";                /* in zephyr/boards/infineon/cyw920829m2evk_02/cyw920829m2evk_02-common.dtsi:25 */
			gpios = < &gpio_prt5 0x2 0x1 >; /* in zephyr/boards/infineon/cyw920829m2evk_02/cyw920829m2evk_02-common.dtsi:26 */
		};
	};

	/* node '/gpio_keys' defined in zephyr/boards/infineon/cyw920829m2evk_02/cyw920829m2evk_02-common.dtsi:30 */
	gpio_keys {
		compatible = "gpio-keys"; /* in zephyr/boards/infineon/cyw920829m2evk_02/cyw920829m2evk_02-common.dtsi:31 */

		/* node '/gpio_keys/user_btn0' defined in zephyr/boards/infineon/cyw920829m2evk_02/cyw920829m2evk_02-common.dtsi:33 */
		user_bt0: user_btn0 {
			label = "SW_1";                  /* in zephyr/boards/infineon/cyw920829m2evk_02/cyw920829m2evk_02-common.dtsi:34 */
			gpios = < &gpio_prt0 0x5 0x11 >; /* in zephyr/boards/infineon/cyw920829m2evk_02/cyw920829m2evk_02-common.dtsi:35 */
			zephyr,code = < 0xb >;           /* in zephyr/boards/infineon/cyw920829m2evk_02/cyw920829m2evk_02-common.dtsi:36 */
		};

		/* node '/gpio_keys/user_btn1' defined in zephyr/boards/infineon/cyw920829m2evk_02/cyw920829m2evk_02-common.dtsi:39 */
		user_bt1: user_btn1 {
			label = "SW_2";                  /* in zephyr/boards/infineon/cyw920829m2evk_02/cyw920829m2evk_02-common.dtsi:40 */
			gpios = < &gpio_prt1 0x0 0x11 >; /* in zephyr/boards/infineon/cyw920829m2evk_02/cyw920829m2evk_02-common.dtsi:41 */
			zephyr,code = < 0x2 >;           /* in zephyr/boards/infineon/cyw920829m2evk_02/cyw920829m2evk_02-common.dtsi:42 */
		};
	};
};
